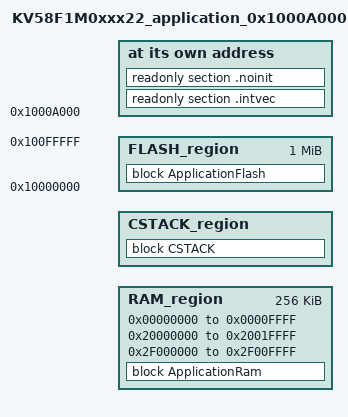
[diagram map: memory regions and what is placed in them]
/*###ICF### Section handled by ICF editor, don't touch! ****/
/*-Editor annotation file-*/
/* IcfEditorFile="$TOOLKIT_DIR$\config\ide\IcfEditor\cortex_v1_0.xml" */
/*-Memory Regions-*/
define symbol __ICFEDIT_region_FLASH_start__   = 0x10000000;
define symbol __ICFEDIT_region_FLASH_end__     = 0x100fffff;  // 1MB
//define symbol __ICFEDIT_region_ITCM_start__  = 0x410;
define symbol __ICFEDIT_region_ITCM_start__    = 0;
define symbol __ICFEDIT_region_ITCM_end__      = 0x0000ffff;
define symbol __ICFEDIT_region_DTCM_start__    = 0x20000000;
define symbol __ICFEDIT_region_DTCM_end__      = 0x2001ffff;
define symbol __ICFEDIT_region_OCRAM_start__   = 0x2f000000;
define symbol __ICFEDIT_region_OCRAM_end__     = 0x2f00ffff;
/*-Specials-*/
define symbol __ICFEDIT_intvec_start__ = __ICFEDIT_region_FLASH_start__+ 0x0000A000;  /*-User Application Base-*/

/*-Sizes-*/
define symbol __ICFEDIT_size_cstack__ = (4*1024);
define symbol __ICFEDIT_size_heap__   = (0*1024);
/**** End of ICF editor section. ###ICF###*/

define exported symbol __VECTOR_TABLE      = __ICFEDIT_region_FLASH_start__;
define exported symbol __VECTOR_RAM        = __ICFEDIT_region_ITCM_start__;

define exported symbol __BOOT_STACK_ADDRESS = __ICFEDIT_region_ITCM_end__ - 8;

define symbol __code_start__ = __ICFEDIT_region_FLASH_start__ + 0x00000410;

define memory mem with size = 4G;
define region FLASH_region   = mem:[from __ICFEDIT_region_FLASH_start__   to __ICFEDIT_region_FLASH_end__];
define region RAM_region   = mem:[from __ICFEDIT_region_ITCM_start__   to __ICFEDIT_region_ITCM_end__] 
                           | mem:[from __ICFEDIT_region_DTCM_start__ to __ICFEDIT_region_DTCM_end__]
                           | mem:[from __ICFEDIT_region_OCRAM_start__ to __ICFEDIT_region_OCRAM_end__];
          
define block CSTACK    with alignment = 8, size = __ICFEDIT_size_cstack__   { };
define block HEAP      with alignment = 8, size = __ICFEDIT_size_heap__     { };

define region CSTACK_region = mem:[from __ICFEDIT_region_ITCM_end__ -__ICFEDIT_size_cstack__+1 to __ICFEDIT_region_ITCM_end__];

initialize manually { readwrite };
initialize manually { section .data};
initialize manually { section .textrw };
do not initialize  { section .noinit };

define block CodeRelocate { section .textrw_init };
define block CodeRelocateRam { section .textrw };

define block ApplicationFlash { readonly, block CodeRelocate };
define block ApplicationRam { readwrite, block CodeRelocateRam, block HEAP };
place at address mem:__ICFEDIT_intvec_start__ { readonly section .intvec, readonly section .noinit };
place in CSTACK_region  { block CSTACK };
place in FLASH_region { block ApplicationFlash };
place in RAM_region   { block ApplicationRam };

